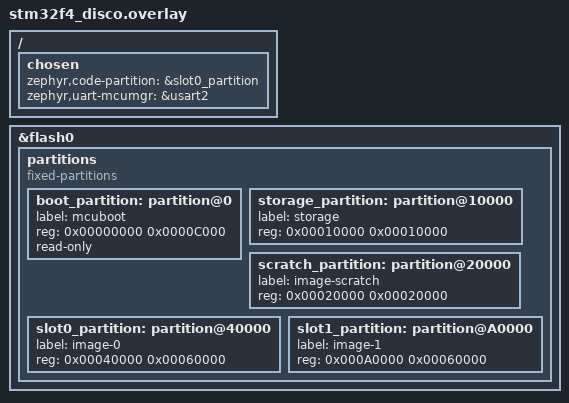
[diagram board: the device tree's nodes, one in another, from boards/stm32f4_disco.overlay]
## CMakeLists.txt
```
cmake_minimum_required(VERSION 3.20.0)

find_package(Zephyr REQUIRED HINTS $ENV{ZEPHYR_BASE})
project(zdfu)

if(NOT (DEFINED SYSBUILD))
  message(FATAL_ERROR "This project must be built with sysbuild.")
endif()

set(SRC_DIR "src")
set(SRC_FILES
    "${SRC_DIR}/main.cpp"
)

target_sources(app PRIVATE ${SRC_FILES})
```

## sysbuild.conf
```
SB_CONFIG_BOOTLOADER_MCUBOOT=y

# The key was generated according to documentation on mcuboot.md and is currently being kept in a 
# different git private repository (github.com/TSMotter/privkeys).
# This option is commented out here because it is currently being set in command line during build.
# The actual west command used to build can be checked at `bbuild.sh` script
#SB_CONFIG_BOOT_SIGNATURE_KEY_FILE=\""$(pwd)/../privkeys/root-rsa-2048-01.pem"\"
```

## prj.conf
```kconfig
#===================================================================================================
# Added by author
#===================================================================================================
CONFIG_CPP=y
CONFIG_PRINTK=y
CONFIG_LOG=y
CONFIG_LOG_PRINTK=y

# Ensure an MCUboot-compatible binary is generated.
CONFIG_BOOTLOADER_MCUBOOT=y

#===================================================================================================
# Copy/Paste from ~/zephyrproject/zephyr/samples/subsys/mgmt/mcumgr/smp_svr/prj.conf
#===================================================================================================
# Enable MCUmgr and dependencies.
CONFIG_NET_BUF=y
CONFIG_ZCBOR=y
CONFIG_CRC=y
CONFIG_MCUMGR=y
CONFIG_STREAM_FLASH=y
CONFIG_FLASH_MAP=y
# Enable flash operations.
CONFIG_FLASH=y
# Required by the `taskstat` command.
CONFIG_THREAD_MONITOR=y
# Support for taskstat command
CONFIG_MCUMGR_GRP_OS_TASKSTAT=y
# Enable statistics and statistic names.
CONFIG_STATS=y
CONFIG_STATS_NAMES=y
# Enable most core commands.
CONFIG_FLASH=y
CONFIG_IMG_MANAGER=y
CONFIG_MCUMGR_GRP_IMG=y
CONFIG_MCUMGR_GRP_OS=y
CONFIG_MCUMGR_GRP_STAT=y

#===================================================================================================
# Copy/Paste from ~/zephyrproject/zephyr/samples/subsys/mgmt/mcumgr/smp_svr/overlay-serial-console.conf
#===================================================================================================
# Enable the serial MCUmgr transport.
CONFIG_BASE64=y
CONFIG_MCUMGR_TRANSPORT_UART=y
CONFIG_CONSOLE=y
```

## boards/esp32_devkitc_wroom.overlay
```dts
/ {
    chosen {
        zephyr,code-partition = &slot0_partition;
        zephyr,uart-mcumgr = &uart0;
    };
    
	aliases {
        led0 = &led0;
        led3 = &led0;
	};

	leds {
		compatible = "gpio-leds";
		led0: led_0 {
			gpios = <&gpio0 2 GPIO_ACTIVE_HIGH>;
			label = "LED 0";
		};
	};
};
```

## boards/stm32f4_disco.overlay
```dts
/ {
    chosen {
        zephyr,code-partition = &slot0_partition;
        zephyr,uart-mcumgr = &usart2;
    };
};

&flash0 {
    status = "okay";
    partitions {
        compatible = "fixed-partitions";
        #address-cells = <1>;
        #size-cells = <1>;

        /*
            Bootloader
            Sectors 0 (16kB) + 1 (16kB) + 2 (16kB) = 48kB
        */
        boot_partition: partition@0 {
            label = "mcuboot";
            reg = <0x00000000 0x0000C000>;
            read-only;
        };

        /*
            Unused
            Sector 3 (16kB) = 16kB
        */

        /*
            Storage
            Sector 4 (64kB) = 64kB
        */
        storage_partition: partition@10000 {
            label = "storage";
            reg = <0x00010000 0x00010000>;
        };

        /*
            Scratch
            Sector 5 (128kB) = 128kB
        */
        scratch_partition: partition@20000 {
               label = "image-scratch";
               reg = <0x00020000 0x00020000>;
        };

        /*
            Slot 0
            Sectors 6 (128kB) + 7 (128kB) + 8 (128kB) = 384kB
        */
        slot0_partition: partition@40000 {
            label = "image-0";
            reg = <0x00040000 0x00060000>;
        };

        /*
            Slot 1
            Sectors 9 (128kB) + 10 (128kB) + 11 (128kB) = 384kB
        */
        slot1_partition: partition@A0000 {
            label = "image-1";
            reg = <0x000A0000 0x00060000>;
        };
    };
};
```

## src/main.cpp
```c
#include <zephyr/kernel.h>
#include <zephyr/drivers/gpio.h>
#include <zephyr/logging/log.h>

#include <zephyr/stats/stats.h>
#include <zephyr/mgmt/mcumgr/grp/stat_mgmt/stat_mgmt.h>

/***************************************************************************************************
 * LOGs
 ***************************************************************************************************/
#define LOG_LEVEL LOG_LEVEL_DBG
LOG_MODULE_REGISTER(zdfu);

/***************************************************************************************************
 * SMP Server Statistics Management
 ***************************************************************************************************/
// Define an example stats group
STATS_SECT_START(smp_server_stats)
STATS_SECT_ENTRY(counter_stat)
STATS_SECT_END;

// Assign a name to the `counter_stat` stat.
STATS_NAME_START(smp_server_stats)
STATS_NAME(smp_server_stats, counter_stat)
STATS_NAME_END(smp_server_stats);

// Define an instance of the stats group.
STATS_SECT_DECL(smp_server_stats) smp_server_stats;

/***************************************************************************************************
 * LED definition and initialization
 ***************************************************************************************************/
#define LED0_NODE DT_ALIAS(led0)
static const struct gpio_dt_spec led0_dt_spec = GPIO_DT_SPEC_GET_OR(LED0_NODE, gpios, {0});

/***************************************************************************************************
 * Choose to build one of the 2 binaries
 ***************************************************************************************************/
// #define Binary_One
#define Binary_Two


#ifdef Binary_One

#define BLINK_PERIOD 1000

#elif defined(Binary_Two)

#define BLINK_PERIOD 100

#endif


int main(void)
{
    int rc = 0;

    rc = STATS_INIT_AND_REG(smp_server_stats, STATS_SIZE_32, "smp_server_stats");
    if (rc < 0)
    {
        LOG_ERR("Error initializing stats system [%d]", rc);
        return 0;
    }

    rc = gpio_is_ready_dt(&led0_dt_spec);
    if (rc < 0)
    {
        LOG_ERR("Error initializing led0 [%d]", rc);
        return 0;
    }

    rc = gpio_pin_configure_dt(&led0_dt_spec, GPIO_OUTPUT_ACTIVE);
    if (rc < 0)
    {
        LOG_ERR("Error configuring led0 pin [%d]", rc);
        return 0;
    }

    while (1)
    {
        rc = gpio_pin_toggle_dt(&led0_dt_spec);
        if (rc < 0)
        {
            LOG_ERR("Error toggling led0 [%d]", rc);
            return 0;
        }
        k_msleep(BLINK_PERIOD);
        STATS_INC(smp_server_stats, counter_stat);
    }
    return 0;
}
```
